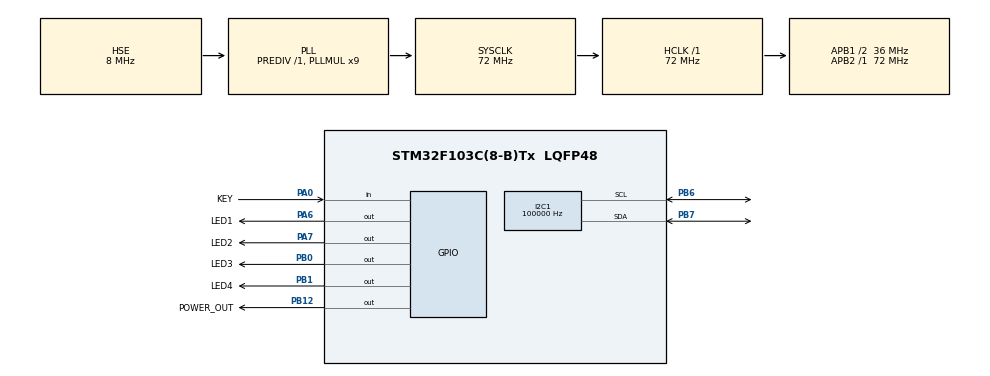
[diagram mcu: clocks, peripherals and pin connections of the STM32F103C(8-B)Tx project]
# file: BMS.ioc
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FREERTOS.Tasks01=defaultTask,24,64,StartDefaultTask,Default,NULL,Dynamic,NULL,NULL;BQREAD_TASK,24,128,bqRead_task,As weak,NULL,Dynamic,NULL,NULL;SysStateTask,24,128,sysState_task,As weak,NULL,Dynamic,NULL,NULL
FREERTOS.configMINIMAL_STACK_SIZE=64
I2C1.ClockSpeed=100000
I2C1.I2C_Mode=I2C_Fast
Mcu.Family=STM32F1
Mcu.Name=STM32F103C(8-B)Tx
Mcu.Package=LQFP48
NVIC.I2C1_ER_IRQn=true\:5\:0\:false\:false\:true\:true\:true\:true\:true
NVIC.I2C1_EV_IRQn=true\:5\:0\:false\:false\:true\:true\:true\:true\:true
NVIC.PriorityGroup=NVIC_PRIORITYGROUP_4
NVIC.TIM4_IRQn=true\:15\:0\:false\:false\:true\:false\:false\:true\:true
NVIC.TimeBase=TIM4_IRQn
NVIC.TimeBaseIP=TIM4
PA0-WKUP.GPIO_Label=KEY
PA0-WKUP.Signal=GPIO_Input
PA13.Mode=Serial_Wire
PA13.Signal=SYS_JTMS-SWDIO
PA14.Mode=Serial_Wire
PA14.Signal=SYS_JTCK-SWCLK
PA6.GPIO_Label=LED1
PA6.GPIO_PuPd=GPIO_PULLUP
PA6.PinState=GPIO_PIN_SET
PA6.Signal=GPIO_Output
PA7.GPIO_Label=LED2
PA7.GPIO_PuPd=GPIO_PULLUP
PA7.PinState=GPIO_PIN_SET
PA7.Signal=GPIO_Output
PB0.GPIO_Label=LED3
PB0.GPIO_PuPd=GPIO_PULLUP
PB0.PinState=GPIO_PIN_SET
PB0.Signal=GPIO_Output
PB1.GPIO_Label=LED4
PB1.GPIO_PuPd=GPIO_PULLUP
PB1.PinState=GPIO_PIN_SET
PB1.Signal=GPIO_Output
PB12.GPIO_Label=POWER_OUT
PB12.Signal=GPIO_Output
PB6.Mode=I2C
PB6.Signal=I2C1_SCL
PB7.Mode=I2C
PB7.Signal=I2C1_SDA
PD0-OSC_IN.Mode=HSE-External-Oscillator
PD0-OSC_IN.Signal=RCC_OSC_IN
PD1-OSC_OUT.Mode=HSE-External-Oscillator
PD1-OSC_OUT.Signal=RCC_OSC_OUT
ProjectManager.HeapSize=0x200
ProjectManager.StackSize=0x400
ProjectManager.TargetToolchain=MDK-ARM V5.32
RCC.AHBFreq_Value=72000000
RCC.APB1CLKDivider=RCC_HCLK_DIV2
RCC.APB1Freq_Value=36000000
RCC.APB1TimFreq_Value=72000000
RCC.APB2Freq_Value=72000000
RCC.APB2TimFreq_Value=72000000
RCC.HCLKFreq_Value=72000000
RCC.PLLMUL=RCC_PLL_MUL9
RCC.PLLSourceVirtual=RCC_PLLSOURCE_HSE
RCC.SYSCLKFreq_VALUE=72000000
RCC.SYSCLKSource=RCC_SYSCLKSOURCE_PLLCLK
RCC.USBFreq_Value=72000000
VP_FREERTOS_VS_CMSIS_V2.Mode=CMSIS_V2
VP_SYS_VS_tim4.Mode=TIM4
board=custom

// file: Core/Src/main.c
/* USER CODE BEGIN Header */
/**
  ******************************************************************************
  * @file           : main.c
  * @brief          : Main program body
  ******************************************************************************
  * @attention
  *
  * Copyright (c) 2023 STMicroelectronics.
  * All rights reserved.
  *
  * This software is licensed under terms that can be found in the LICENSE file
  * in the root directory of this software component.
  * If no LICENSE file comes with this software, it is provided AS-IS.
  *
  ******************************************************************************
  */
/* USER CODE END Header */
#include "main.h"
#include "cmsis_os.h"
#include "i2c.h"
#include "gpio.h"

/* USER CODE BEGIN Includes */
#include "drv_led.h"
#include "drv_bq78350.h"
#include "SEGGER_RTT.h"
#include "drv_rgb.h"
/* USER CODE END Includes */

void SystemClock_Config(void);
void MX_FREERTOS_Init(void);

int main(void)
{

  /* MCU Configuration--------------------------------------------------------*/

  /* Reset of all peripherals, Initializes the Flash interface and the Systick. */
  HAL_Init();

  /* Configure the system clock */
  SystemClock_Config();

  /* Initialize all configured peripherals */
  MX_GPIO_Init();
  MX_I2C1_Init();
  /* USER CODE BEGIN 2 */
	BQ78350_Init(&hi2c1);
	//SEGGER_RTT_printf(0,"hello rtt!");
	//rgb_init(&htim1);
  /* USER CODE END 2 */

  /* Init scheduler */
  osKernelInitialize();  /* Call init function for freertos objects (in freertos.c) */
  MX_FREERTOS_Init();

  /* Start scheduler */
  osKernelStart();
  /* We should never get here as control is now taken by the scheduler */
  /* Infinite loop */
  while (1)
  {

  }
}

void SystemClock_Config(void)
{
  RCC_OscInitTypeDef RCC_OscInitStruct = {0};
  RCC_ClkInitTypeDef RCC_ClkInitStruct = {0};

  /** Initializes the RCC Oscillators according to the specified parameters
  * in the RCC_OscInitTypeDef structure.
  */
  RCC_OscInitStruct.OscillatorType = RCC_OSCILLATORTYPE_HSE;
  RCC_OscInitStruct.HSEState = RCC_HSE_ON;
  RCC_OscInitStruct.HSEPredivValue = RCC_HSE_PREDIV_DIV1;
  RCC_OscInitStruct.HSIState = RCC_HSI_ON;
  RCC_OscInitStruct.PLL.PLLState = RCC_PLL_ON;
  RCC_OscInitStruct.PLL.PLLSource = RCC_PLLSOURCE_HSE;
  RCC_OscInitStruct.PLL.PLLMUL = RCC_PLL_MUL9;
  if (HAL_RCC_OscConfig(&RCC_OscInitStruct) != HAL_OK)
  {
    Error_Handler();
  }

  /** Initializes the CPU, AHB and APB buses clocks
  */
  RCC_ClkInitStruct.ClockType = RCC_CLOCKTYPE_HCLK|RCC_CLOCKTYPE_SYSCLK
                              |RCC_CLOCKTYPE_PCLK1|RCC_CLOCKTYPE_PCLK2;
  RCC_ClkInitStruct.SYSCLKSource = RCC_SYSCLKSOURCE_PLLCLK;
  RCC_ClkInitStruct.AHBCLKDivider = RCC_SYSCLK_DIV1;
  RCC_ClkInitStruct.APB1CLKDivider = RCC_HCLK_DIV2;
  RCC_ClkInitStruct.APB2CLKDivider = RCC_HCLK_DIV1;

  if (HAL_RCC_ClockConfig(&RCC_ClkInitStruct, FLASH_LATENCY_2) != HAL_OK)
  {
    Error_Handler();
  }
}

void HAL_TIM_PeriodElapsedCallback(TIM_HandleTypeDef *htim)
{
  if (htim->Instance == TIM4) {
    HAL_IncTick();
  }
}

void Error_Handler(void)
{
  __disable_irq();
  while (1)
  {
  }
}

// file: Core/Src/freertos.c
/* USER CODE BEGIN Header */
/**
  ******************************************************************************
  * File Name          : freertos.c
  * Description        : Code for freertos applications
  ******************************************************************************
  * @attention
  *
  * Copyright (c) 2023 STMicroelectronics.
  * All rights reserved.
  *
  * This software is licensed under terms that can be found in the LICENSE file
  * in the root directory of this software component.
  * If no LICENSE file comes with this software, it is provided AS-IS.
  *
  ******************************************************************************
  */
/* USER CODE END Header */

#include "FreeRTOS.h"
#include "task.h"
#include "main.h"
#include "cmsis_os.h"

/* USER CODE BEGIN Includes */
#include "drv_key.h"
#include "drv_bq78350.h"
/* USER CODE END Includes */

/* Definitions for defaultTask */
osThreadId_t defaultTaskHandle;
const osThreadAttr_t defaultTask_attributes = {
  .name = "defaultTask",
  .stack_size = 64 * 4,
  .priority = (osPriority_t) osPriorityNormal,
};
/* Definitions for BQREAD_TASK */
osThreadId_t BQREAD_TASKHandle;
const osThreadAttr_t BQREAD_TASK_attributes = {
  .name = "BQREAD_TASK",
  .stack_size = 128 * 4,
  .priority = (osPriority_t) osPriorityNormal,
};
/* Definitions for SysStateTask */
osThreadId_t SysStateTaskHandle;
const osThreadAttr_t SysStateTask_attributes = {
  .name = "SysStateTask",
  .stack_size = 128 * 4,
  .priority = (osPriority_t) osPriorityNormal,
};

void StartDefaultTask(void *argument);
void bqRead_task(void *argument);
void sysState_task(void *argument);

void MX_FREERTOS_Init(void); /* (MISRA C 2004 rule 8.1) */

void MX_FREERTOS_Init(void) {

  /* Create the thread(s) */
  /* creation of defaultTask */
  defaultTaskHandle = osThreadNew(StartDefaultTask, NULL, &defaultTask_attributes);

  /* creation of BQREAD_TASK */
  BQREAD_TASKHandle = osThreadNew(bqRead_task, NULL, &BQREAD_TASK_attributes);

  /* creation of SysStateTask */
  SysStateTaskHandle = osThreadNew(sysState_task, NULL, &SysStateTask_attributes);

}

void StartDefaultTask(void *argument)
{
  /* USER CODE BEGIN StartDefaultTask */
  /* Infinite loop */
  for(;;)
  {
		keyStateMachine();
		//HAL_GPIO_TogglePin(GPIOB,GPIO_PIN_12);
		//HAL_GPIO_WritePin(GPIOB,GPIO_PIN_12,GPIO_PIN_SET);
		osDelay(10);
  }
  /* USER CODE END StartDefaultTask */
}

__weak void bqRead_task(void *argument)
{
  for(;;)
  {
    osDelay(1);
  }
}

__weak void sysState_task(void *argument)
{
  for(;;)
  {
    osDelay(1);
  }
}
